# STM32H523xx register map
File version: 1.0
Registers are 32-bit, read-write, reset 0x0 unless marked. A register's access mark holds for its fields unless they carry their own. Offsets are from the block's base; [hi:lo] are bit positions; {n}, {i} and the like mark numbered series.

## SBS — System configuration, Boot and Security
Base 0x44000400
Same registers: SBS_S 0x54000400
0x10 HDPLCR — SBS HDPL Control Register
  [7:0] INCR_HDPL — Increment HDPL value
0x14 HDPLSR — SBS HDPL Status Register
  [7:0] HDPL — HDPL value
0x18 NEXTHDPLCR — NEXT HDPL Control Register
  [1:0] NEXTHDPL — NEXTHDPL value
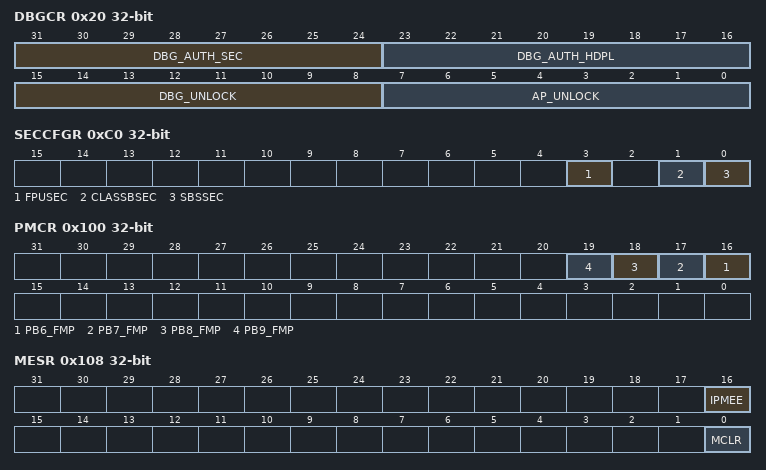
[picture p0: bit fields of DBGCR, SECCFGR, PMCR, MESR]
0x20 DBGCR — SBS Debug Control Register
  [31:24] DBG_AUTH_SEC — Open the non-secured and secured debugs
  [23:16] DBG_AUTH_HDPL — HDPL value when the debug should be effectively opened
  [15:8] DBG_UNLOCK — Open the debug when DBG_AUTH_HDPL is reached
  [7:0] AP_UNLOCK — Open the Access Port
0x24 DBGLOCKR — SBS Debug Lock Register
  [7:0] DBGCFG_LOCK — SBS_DBGLOCKR_DBGCFG_LOCK value
0x34 RSSCMDR — SBS RSS Command Register
  [15:0] RSSCMD — command to be executed by the RSS
0xA0 EPOCHSELCR — EPOCH Selection Register
  [1:0] EPOCH_SEL — Select EPOCH sent to SAES IP to encrypt/decrypt keys
0xC0 SECCFGR — SBS Security Mode Configuration
  [3] FPUSEC — FPU SBS security enable
  [1] CLASSBSEC — ClassB SBS security enable
  [0] SBSSEC — SBS clock control security enable
0x100 PMCR — SBS Product Mode & Config Register
  [n+10] PB{n}_FMP (n=6..9) — Fast-mode Plus command on PB({n})
0x104 FPUIMR — SBS FPU Interrupt Mask Register
  [5:0] FPU_IE — All FPU interrupts enable
0x108 MESR — SBS Memory Erase Status Register
  [16] IPMEE — Status of End of Erase for ICache and PKA RAMs
  [0] MCLR — Status of Erase after Reset
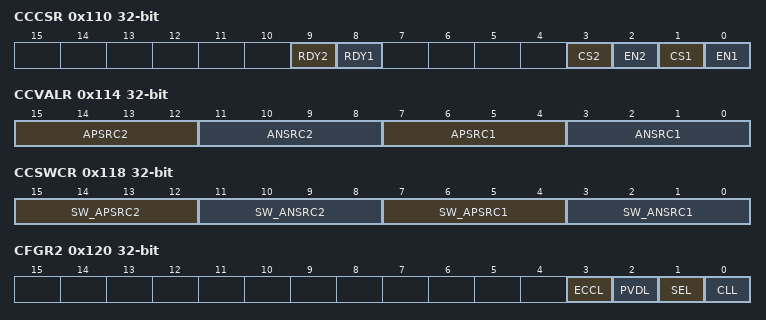
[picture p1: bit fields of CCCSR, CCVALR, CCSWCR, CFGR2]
0x110 CCCSR — SBS Compensation Cell Control & Status Register
  [9] RDY2 — VDDIO compensation cell ready flag
  [8] RDY1 — VDD compensation cell ready flag
  [3] CS2 — Code selection for VDDIO power rail
  [2] EN2 — Enable compensation cell for VDDIO power rail
  [1] CS1 — Code selection for VDD power rail
  [0] EN1 — Enable compensation cell for VDD power rail
0x114 CCVALR — SBS Compensation Cell Value Register
  [15:12] APSRC2 — PMOS compensation value
  [11:8] ANSRC2 — NMOS compensation value
  [7:4] APSRC1 — PMOS compensation value
  [3:0] ANSRC1 — NMOS compensation value
0x118 CCSWCR — SBS Compensation Cell for I/Os sw code Register
  [15:12] SW_APSRC2 — PMOS compensation code for VDDIO Power Rail
  [11:8] SW_ANSRC2 — NMOS compensation code for VDDIO Power Rail
  [7:4] SW_APSRC1 — PMOS compensation code for VDD Power Rail
  [3:0] SW_ANSRC1 — NMOS compensation code for VDD Power Rail
0x120 CFGR2 — SBS Class B Register
  [3] ECCL — Flash ECC Lock
  [2] PVDL — PVD Lock
  [1] SEL — SRAM ECC Lock
  [0] CLL — Core Lockup Lock
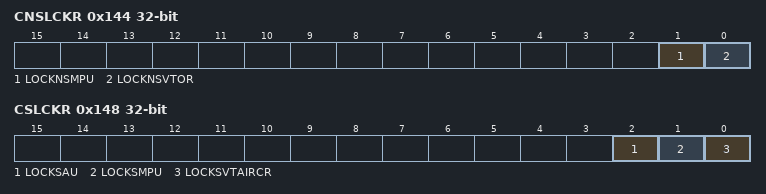
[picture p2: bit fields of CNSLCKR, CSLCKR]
0x144 CNSLCKR — SBS CPU Non-secure Lock Register
  [1] LOCKNSMPU — Disable Non-Secure MPU registers writes by SW or debug agent
  [0] LOCKNSVTOR — Disable VTOR_NS register writes by SW or debug agent
0x148 CSLCKR — SBS CPU Secure Lock Register
  [2] LOCKSAU — Disable changes to SAU registers
  [1] LOCKSMPU — Disable changes to the secure MPU registers writes by SW or debug agent
  [0] LOCKSVTAIRCR — Disable changes to the secure vector table address, handling of system faults
0x14C ECCNMIR — SBS FLITF ECC NMI MASK Register
  [0] ECCNMI_MASK_EN — Disable NMI in case of double ECC error in flash interface

## VREFBUF
Base 0x44007400
Same registers: VREFBUF_S 0x54007400
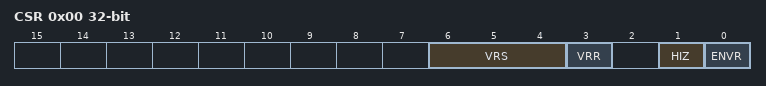
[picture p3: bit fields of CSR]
0x00 CSR — VREFBUF control and status register
  [6:4] VRS — Voltage reference scale
    {v}=SCALE{v} (Voltage reference scale {v} (VREF_OUT{v+1})) (v=0..3)
  [3] VRR — Voltage reference buffer ready
  [1] HIZ — High impedance mode
  [0] ENVR — Voltage reference buffer enable
0x04 CCR — VREFBUF calibration and control register
  [5:0] TRIM — TRIM[5:0] bits (Trimming code)

## PWR — Power Control
Base 0x44020800
Same registers: PWR_S 0x54020800
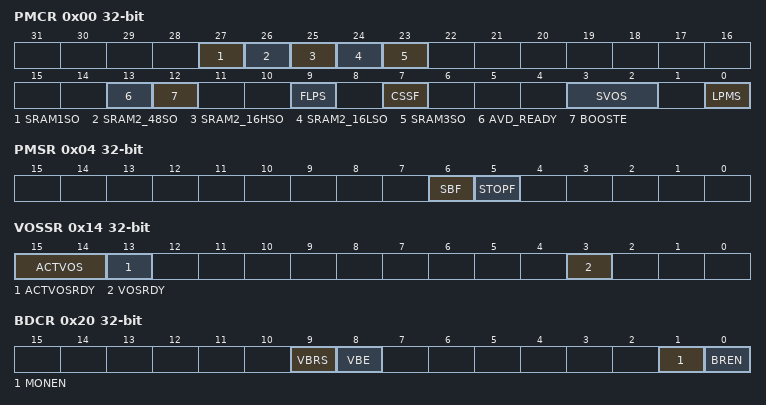
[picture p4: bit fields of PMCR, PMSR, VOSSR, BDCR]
0x00 PMCR — Power mode control register
  [27] SRAM1SO
  [26] SRAM2_48SO
  [25] SRAM2_16HSO
  [24] SRAM2_16LSO
  [23] SRAM3SO
  [13] AVD_READY
  [12] BOOSTE
  [9] FLPS
  [7] CSSF
  [3:2] SVOS
    3=SCALE3 (Select voltage scale 3 when system enters STOP mode); 2=SCALE4 (Select voltage scale 4 when system enters STOP mode); 1=SCALE5 (Select voltage scale 5 when system enters STOP mode)
  [0] LPMS
    0=STOP_MODE (STOP 0 mode); 1=STANDBY_MODE
0x04 PMSR — Power mode status register
  [6] SBF, [5] STOPF
0x10 VOSCR — Voltage scaling control register
  [5:4] VOS
    3=SCALE0 (Voltage scaling range 0); 2=SCALE1 (Voltage scaling range 1); 1=SCALE2 (Voltage scaling range 2); 0=SCALE3 (Voltage scaling range 3)
0x14 VOSSR — Voltage sacling status register
  [15:14] ACTVOS, [13] ACTVOSRDY, [3] VOSRDY
0x20 BDCR — BacKup domain control register
  [9] VBRS
    0=RESISTOR_5K (Charge the battery through a 5 kO resistor); 1=RESISTOR_1_5K (Charge the battery through a 1.5 kO resistor)
  [8] VBE
  [1] MONEN
  [0] BREN
0x24 DBPCR — DBP control register
  [0] DBP
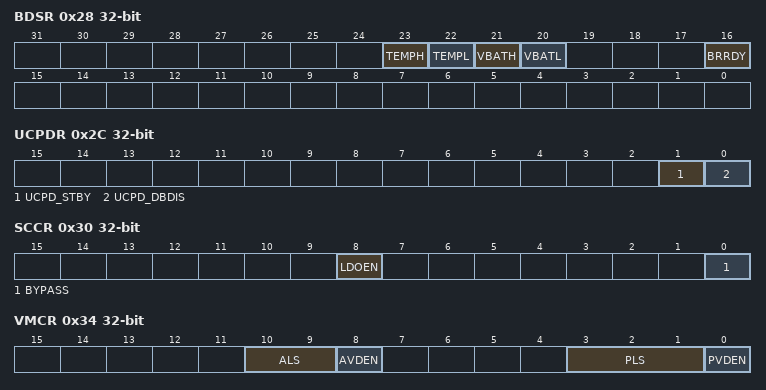
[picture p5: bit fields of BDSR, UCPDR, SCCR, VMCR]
0x28 BDSR — BacKup domain status register
  [23] TEMPH, [22] TEMPL, [21] VBATH, [20] VBATL, [16] BRRDY
0x2C UCPDR — Usb typeC and Power Delivery Register
  [1] UCPD_STBY, [0] UCPD_DBDIS
0x30 SCCR — Supply configuration control register
  [8] LDOEN, [0] BYPASS
0x34 VMCR — Voltage Monitor Control Register
  [10:9] ALS
    0=AVDLEVEL_0 (Analog Voltage threshold detected by AVD 1.7 V); 1=AVDLEVEL_1 (Analog Voltage threshold detected by AVD 2.1 V); 2=AVDLEVEL_2 (Analog Voltage threshold detected by AVD 2.5 V); 3=AVDLEVEL_3 (Analog Voltage threshold detected by AVD 2.8 V)
  [8] AVDEN
  [3:1] PLS
    0=PVDLEVEL_0 (Voltage threshold detected by PVD 1.95 V); 1=PVDLEVEL_1 (Voltage threshold detected by PVD 2.10 V); 2=PVDLEVEL_2 (Voltage threshold detected by PVD 2.25 V); 3=PVDLEVEL_3 (Voltage threshold detected by PVD 2.40 V); 4=PVDLEVEL_4 (Voltage threshold detected by PVD 2.55 V); 5=PVDLEVEL_5 (Voltage threshold detected by PVD 2.70 V); 6=PVDLEVEL_6 (Voltage threshold detected by PVD 2.85 V); 7=PVDLEVEL_7
  [0] PVDEN
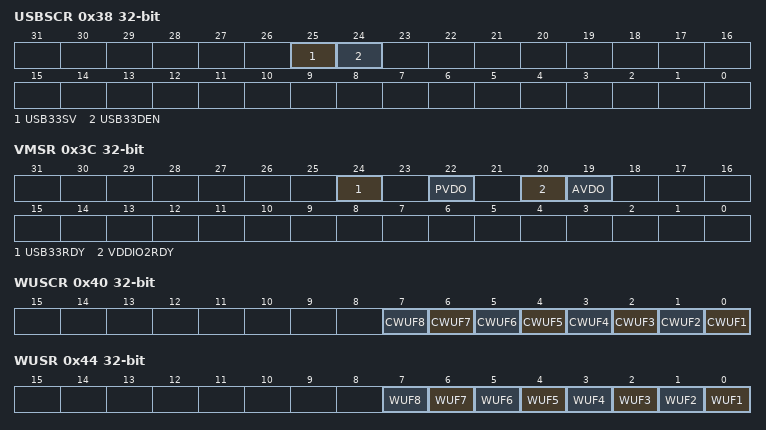
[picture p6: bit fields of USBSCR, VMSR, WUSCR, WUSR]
0x38 USBSCR — USB Supply Control Register
  [25] USB33SV, [24] USB33DEN
0x3C VMSR — Status Register Voltage Monitoring
  [24] USB33RDY, [22] PVDO, [20] VDDIO2RDY, [19] AVDO
0x40 WUSCR — WakeUP status clear register
  [n-1] CWUF{n} (n=1..8)
0x44 WUSR — WakeUP status Register
  [n-1] WUF{n} (n=1..8)
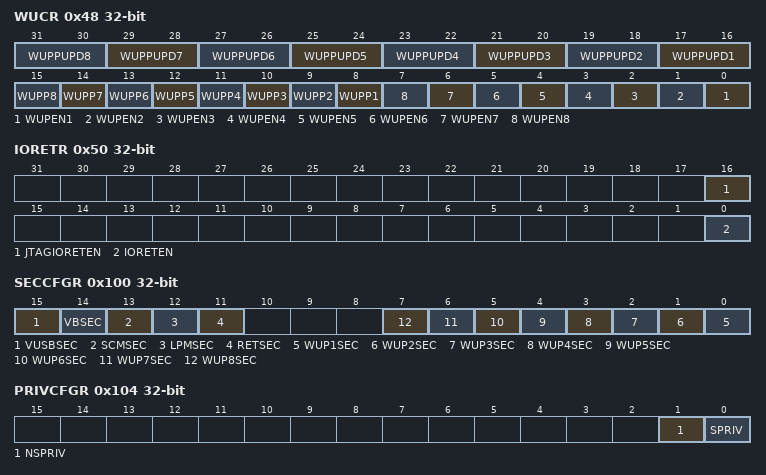
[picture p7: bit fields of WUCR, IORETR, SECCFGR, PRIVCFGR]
0x48 WUCR — WakeUP configuration register
  [2n+15:2n+14] WUPPUPD{n} (n=1..8), [n+7] WUPP{n} (n=1..8), [n-1] WUPEN{n} (n=1..8)
0x50 IORETR — IO RETention Register
  [16] JTAGIORETEN, [0] IORETEN
0x100 SECCFGR — Security configuration register
  [15] VUSBSEC, [14] VBSEC, [13] SCMSEC, [12] LPMSEC, [11] RETSEC, [n-1] WUP{n}SEC (n=1..8)
0x104 PRIVCFGR — Privilege configuration register
  [1] NSPRIV, [0] SPRIV
